# NUC123AE_v1 register map
File version: 1.0
Registers are 32-bit, read-write, reset 0x0 unless marked. A register's access mark holds for its fields unless they carry their own. Offsets are from the block's base; [hi:lo] are bit positions; {n}, {i} and the like mark numbered series; 'fields as' and 'values as' point back to an identical list.

## GCR — GCR Register Map
Base 0x50000000
0x00 PDID ro reset 0x10000 (reset mask 0xFFFF0000) — Part Device Identification Number Register
  [31:0] PDID — Part Device Identification Number. This register reflects the device part number code. S/W can read this register to identify which device is used.
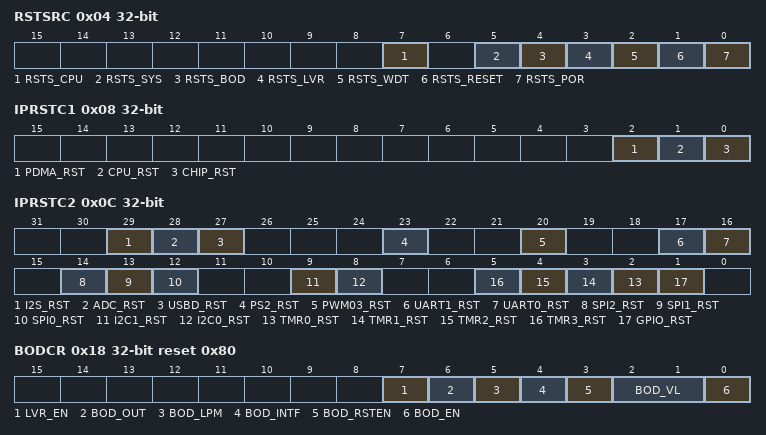
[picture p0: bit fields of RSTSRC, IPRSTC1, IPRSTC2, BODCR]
0x04 RSTSRC (reset mask 0xFFFFFF00) — System Reset Source Register
  [7] RSTS_CPU — The RSTS_CPU flag is set by hardware if software writes CPU_RST (IPRSTC1[1]) 1 to reset Cortex-M0 CPU kernel and Flash memory controller (FMC). Software can write 1 to clear this bit to zero.
    0=No reset from CPU; 1=Cortex-M0 CPU kernel and FMC are reset by software setting CPU_RST to 1
  [5] RSTS_SYS — The RSTS_SYS flag is set by the "reset signal" from the Cortex_M0 kernel to indicate the previous reset source. Software can write 1 to clear this bit to zero.
    0=No reset from Cortex_M0; 1=Cortex_M0 had issued the reset signal to reset the system by software writing 1 to bit SYSRESETREQ(AIRCR[2], Application Interrupt and Reset Control Register, address = 0xE000ED0C) in system control registers of Cortex_M0 kernel
  [4] RSTS_BOD — The RSTS_BOD flag is set by the "reset signal" from the Brown-out-Detector to indicate the previous reset source. Software can write 1 to clear this bit to zero.
    0=No reset from BOD; 1=BOD had issued the reset signal to reset the system
  [3] RSTS_LVR — The RSTS_LVR flag is set by the "reset signal" from the Low-Voltage-Reset controller to indicate the previous reset source. Software can write 1 to clear this bit to zero.
    0=No reset from LVR; 1=LVR controller had issued the reset signal to reset the system
  [2] RSTS_WDT — The RSTS_WDT flag is set by the "reset signal" from the watchdog timer to indicate the previous reset source. Software can write 1 to clear this bit to zero.
    0=No reset from watchdog timer; 1=Watchdog timer had issued the reset signal to reset the system
  [1] RSTS_RESET — The RSTS_RESET flag is set by the "reset signal" from the /RESET pin to indicate the previous reset source. Software can write 1 to clear this bit to zero.
    0=No reset from /RESET pin; 1=Pin /RESET had issued the reset signal to reset the system
  [0] RSTS_POR — The RSTS_POR flag is set by the "reset signal" from the Power-On Reset (POR) controller or bit CHIP_RST (IPRSTC1[0]) to indicate the previous reset source. Software can write 1 to clear this bit to zero.
    0=No reset from POR or CHIP_RST; 1=Power-On Reset (POR) or CHIP_RST had issued the reset signal to reset the system
0x08 IPRSTC1 — IP Reset Control Register1
  [2] PDMA_RST — PDMA Controller Reset (Write-protection). Setting this bit to 1 will generate a reset signal to the PDMA. User need to set this bit to 0 to release from reset state. This bit is the protected bit, It means programming this bit needs to write "59h", "16h", "88h" to address 0x5000_0100 to disable register protection. Refer to the register REGWRPROT at address GCR_BA+0x100.
    0=PDMA controller normal operation; 1=PDMA controller reset
  [1] CPU_RST — CPU kernel one-shot reset (Write-protection Bit). Setting this bit will only reset the CPU kernel and Flash Memory Controller(FMC), and this bit will automatically return to 0 after the 2 clock cycles. This bit is the protected bit, It means programming this bit needs to write "59h", "16h", "88h" to address 0x5000_0100 to disable register protection. Refer to the register REGWRPROT at address GCR_BA+0x100
    0=CPU normal operation; 1=CPU one-shot reset
  [0] CHIP_RST — CHIP One-shot Reset (Write-protection Bit). Setting this bit will reset the whole chip, including CPU kernel and all peripherals, and this bit will automatically return to 0 after the 2 clock cycles. The CHIP_RST is same as the POR reset, all the chip controllers is reset and the chip setting from flash are also reload. For the difference between CHIP_RST and SYSRESETREQ, please refer to section 5.2.2. This bit is the protected bit, which means programming it needs to write "59h", "16h", "88h" to address 0x5000_0100 to disable register protection. Refer to the register REGWRPROT at address GCR_BA+0x100
    0=CHIP normal operation; 1=CHIP one-shot reset
0x0C IPRSTC2 — IP Reset Control Register2
  [29] I2S_RST — I2S Controller Reset
    0=I2S controller normal operation; 1=I2S controller reset
  [28] ADC_RST — ADC Controller Reset
    0=ADC controller normal operation; 1=ADC controller reset
  [27] USBD_RST — USB Device Controller Reset
    0=USB device controller normal operation; 1=USB device controller reset
  [23] PS2_RST — PS/2 Controller Reset
    0=PS/2 controller normal operation; 1=PS/2 controller reset
  [20] PWM03_RST — PWM03 controller Reset
    0=PWM03 controller normal operation; 1=PWM03 controller reset
  [17] UART1_RST — UART1 controller Reset
    0=UART1 controller normal operation; 1=UART1 controller reset
  [16] UART0_RST — UART0 controller Reset
    0=UART0 controller normal operation; 1=UART0 controller reset
  [14] SPI2_RST — SPI2 controller Reset
    0=SPI2 controller normal operation; 1=SPI2 controller reset
  [13] SPI1_RST — SPI1 controller Reset
    0=SPI1 controller normal operation; 1=SPI1 controller reset
  [12] SPI0_RST — SPI0 controller Reset
    0=SPI0 controller normal operation; 1=SPI0 controller reset
  [9] I2C1_RST — I2C1 controller Reset
    0=I2C1 controller normal operation; 1=I2C1 controller reset
  [8] I2C0_RST — I2C0 controller Reset
    0=I2C0 controller normal operation; 1=I2C0 controller reset
  [n+2] TMR{n}_RST (n=0..3) — Timer{n} controller Reset
    0=Timer{n} controller normal operation; 1=Timer{n} controller reset
  [1] GPIO_RST — GPIO controller Reset
    0=GPIO controller normal operation; 1=GPIO controller reset
0x18 BODCR reset 0x80 (reset mask 0xFFFFFFF0) — Brown-out Detector Control Register
  [7] LVR_EN — Low Voltage Reset Enable (Write-protection Bit). The LVR function reset the chip when the input power voltage is lower than LVR circuit setting. LVR function is enabled by default. This bit is the protected bit, which means programming it needs to write "59h", "16h", "88h" to address 0x5000_0100 to disable register protection. Refer to the register REGWRPROT at address GCR_BA+0x100.
    0=Low Voltage Reset function Disabled; 1=Low Voltage Reset function Enabled- After enabling the bit, the LVR function will be active with 100uS delay for LVR output stable (Default)
  [6] BOD_OUT — Brown-out Detector Output Status
    0=Brown-out Detector output status is 0, which means the detected voltage is higher than BOD_VL setting or BOD_EN is 0; 1=Brown-out Detector output status is 1, which means the detected voltage is lower than BOD_VL setting. If the BOD_EN is 0, BOD function disabled , this bit always responds to 0
  [5] BOD_LPM — Brown-out Detector Low power Mode (Write-protection Bit). The BOD consumes about 100 uA in Normal mode, the low power mode can reduce the current to about 1/10 but slow the BOD response. This bit is the protected bit, which means programming this needs to write "59h", "16h", "88h" to address 0x5000_0100 to disable register protection. Refer to the register REGWRPROT at address GCR_BA+0x100.
    0=BOD operated in Normal mode (Default); 1=BOD low power mode Enabled
  [4] BOD_INTF — Brown-out Detector Interrupt Flag. Software can write 1 to clear this bit to zero.
    0=Brown-out Detector does not detect any voltage draft at VDD down through or up through the voltage of BOD_VL setting; 1=When Brown-out Detector detects the VDD is dropped down through the voltage of BOD_VL setting or the VDD is raised up through the voltage of BOD_VL setting, this bit is set to 1 and the Brown-out interrupt is requested if Brown-out interrupt is enabled
  [3] BOD_RSTEN — Brown-out Reset Enable (Write-protection Bit). While the BOD function is enabled (BOD_EN high) and BOD interrupt function is enabled (BOD_RSTEN low), BOD will assert an interrupt if BOD_OUT is high. BOD interrupt will keep till to the BOD_EN set to 0. BOD interrupt can be blocked by disabling the NVIC BOD interrupt or disabling BOD function (set BOD_EN low). The default value is set by flash controller user configuration register config0 bit[20]. This bit is the protected bit. It means programming this needs to write "59h", "16h", "88h" to address 0x5000_0100 to disable register protection. Refer to the register REGWRPROT at address GCR_BA+0x100.
    0=Brown-out "INTERRUPT" function Enabled; 1=Brown-out "RESET" function Enabled
  [2:1] BOD_VL — Brown-out Detector Threshold Voltage Selection (Write-protection Bits)
  [0] BOD_EN — Brown-out Detector Enable (Write-protection Bit). The default value is set by flash controller user configuration register config0 bit[23]. This bit is the protected bit, which means programming it needs to write "59h", "16h", "88h" to address 0x5000_0100 to disable register protection. Refer to the register REGWRPROT at address GCR_BA+0x100.
    0=Brown-out Detector function Disabled; 1=Brown-out Detector function Enabled
0x24 PORCR (reset mask 0xFFFFFF00) — Power-On-Reset Controller Register
  [15:0] POR_DIS_CODE — The register is used for the Power-On-Reset enable control (Write-protection Bits). When powered on, the POR circuit generates a reset signal to reset the whole chip function, but noise on the power may cause the POR active again. User can disable internal POR circuit to avoid unpredictable noise to cause chip reset by writing 0x5AA5 to this field. The POR function will become active again when this field is set to another value or chip is reset by other reset source, including: /RESET, Watchdog, LVR reset, BOD reset, ICE reset command and the software-chip reset function. This bit is the protected bit, which means programming it needs to write "59h", "16h", "88h" to address 0x5000_0100 to disable register protection. Refer to the register REGWRPROT at address GCR_BA+0x100.
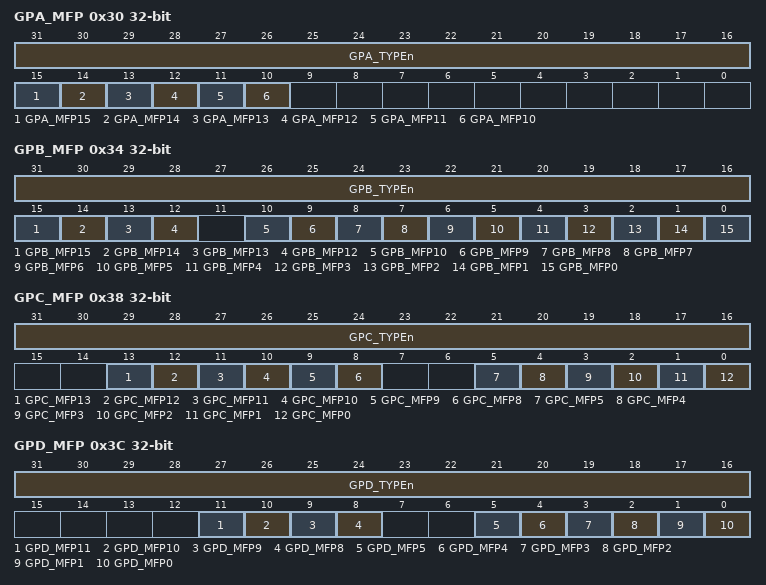
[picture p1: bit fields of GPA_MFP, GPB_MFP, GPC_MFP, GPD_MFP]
0x30 GPA_MFP — GPIOA Multiple Function and Input Type Control Register
  [31:16] GPA_TYPEn — GPA[9:0] are reserved in this chip.
    0=GPIOA[15:0] I/O input Schmitt Trigger function Disabled; 1=GPIOA[15:0] I/O input Schmitt Trigger function Enabled
  [15] GPA_MFP15 — PA.15 Pin Function Selection
  [14] GPA_MFP14 — PA.14 Pin Function Selection
  [13] GPA_MFP13 — PA.13 Pin Function Selection
  [12] GPA_MFP12 — PA.12 Pin Function Selection
  [11] GPA_MFP11 — PA.11 Pin Function Selection
  [10] GPA_MFP10 — PA.10 Pin Function Selection
0x34 GPB_MFP — GPIOB Multiple Function and Input Type Control Register
  [31:16] GPB_TYPEn
    0=GPIOB[15:0] I/O input Schmitt Trigger function Disabled; 1=GPIOB[15:0] I/O input Schmitt Trigger function Enabled
  [15] GPB_MFP15 — PB.15 Pin Function Selection
  [14] GPB_MFP14 — PB.14 Pin Function Selection
  [13] GPB_MFP13 — PB.13 Pin Function Selection
  [12] GPB_MFP12 — PB.12 Pin Function Selection
  [10] GPB_MFP10 — PB.10 Pin Function Selection
  [9] GPB_MFP9 — PB.9 Pin Function Selection
  [8] GPB_MFP8 — PB.8 Pin Function Selection
  [7] GPB_MFP7 — PB.7 Pin Function Selection
  [6] GPB_MFP6 — PB.6 Pin Function Selection
  [5] GPB_MFP5 — PB.
  [4] GPB_MFP4 — PB.4 Pin Function Selection
  [3] GPB_MFP3 — PB.3 Pin Function Selection
  [2] GPB_MFP2 — PB.2 Pin Function Selection
  [1] GPB_MFP1 — PB.1 Pin Function Selection
    0=GPIOB[1] is selected to the pin PB.1; 1=UART0 TXD0 function is selected to the pin PB.1
  [0] GPB_MFP0 — PB.0 Pin Function Selection
    0=GPIOB[0] is selected to the pin PB.0; 1=UART0 RXD0 function is selected to the pin PB.0
0x38 GPC_MFP — GPIOC Multiple Function and Input Type Control Register
  [31:16] GPC_TYPEn
    0=GPIOC[15:0] I/O input Schmitt Trigger function Disabled; 1=GPIOC[15:0] I/O input Schmitt Trigger function Enabled
  [13] GPC_MFP13 — PC.13 Pin Function Selection
  [12] GPC_MFP12 — PC.12 Pin Function Selection
  [11] GPC_MFP11 — PC.11 Pin Function Selection
    0=GPIOC[11] is selected to the pin PC.11; 1=MOSI10 (SPI1 master output, slave input pin-0) function is selected to the pin PC.11
  [10] GPC_MFP10 — PC.10 Pin Function Selection
    0=The GPIOC[10] is selected to the pin PC.10; 1=MISO10 (SPI1 master input, slave output pin-0) function is selected to the pin PC.10
  [9] GPC_MFP9 — PC.9 Pin Function Selection
    0=GPIOC[9] is selected to the pin PC.9; 1=SPICLK1 (SPI1) function is selected to the pin PC.9
  [8] GPC_MFP8 — PC.8 Pin Function Selection
  [5] GPC_MFP5 — PC.5 Pin Function Selection
  [4] GPC_MFP4 — PC.4 Pin Function Selection
  [3] GPC_MFP3 — PC.3 Pin Function Selection
  [2] GPC_MFP2 — PC.2 Pin Function Selection
  [1] GPC_MFP1 — PC.1 Pin Function Selection
  [0] GPC_MFP0 — PC.0 Pin Function Selection
0x3C GPD_MFP — GPIOD Multiple Function and Input Type Control Register
  [31:16] GPD_TYPEn
    0=GPIOD[15:0] I/O input Schmitt Trigger function Disabled; 1=GPIOD[15:0] I/O input Schmitt Trigger function Enabled
  [11] GPD_MFP11 — PD.11 Pin Function Selection
    0=GPIOD[11] is selected to the pin PD.11; 1=/INT1 function is selected to the pin PD.11
  [10] GPD_MFP10 — PD.10 Pin Function Selection
    0=GPIOD[10] is selected to the pin PD.10; 1=CLKO function is selected to the pin PD.10
  [9] GPD_MFP9 — PD.9 Pin Function Selection
  [8] GPD_MFP8 — PD.8 Pin Function Selection
    0=GPIOD[8] is selected to the pin PD8; 1=MOSI10 (SPI1 master output, slave input pin-0) function is selected to the pin PD8
  [5] GPD_MFP5 — PD.5 Pin Function Selection
  [4] GPD_MFP4 — PD.4 Pin Function Selection
  [3] GPD_MFP3 — PD.3 Pin Function Selection
  [2] GPD_MFP2 — PD.2 Pin Function Selection
  [1] GPD_MFP1 — PD.1 Pin Function Selection
  [0] GPD_MFP0 — PD.0 Pin Function Selection
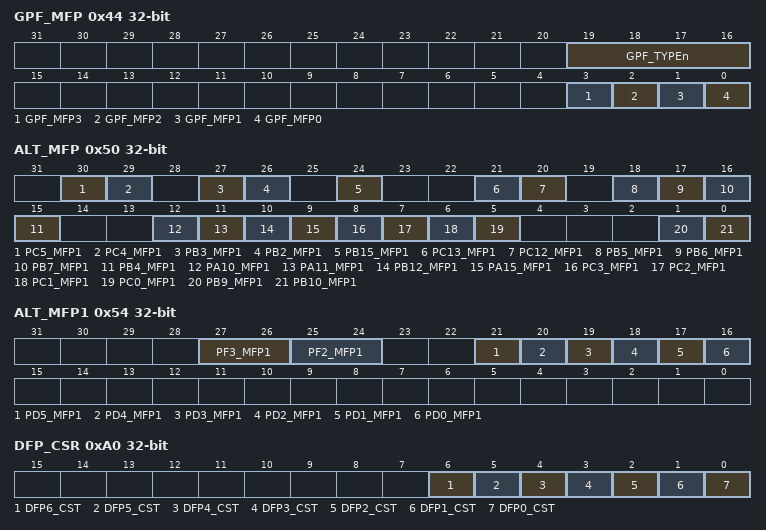
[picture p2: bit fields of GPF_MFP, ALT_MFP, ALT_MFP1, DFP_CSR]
0x44 GPF_MFP (reset mask 0xFFFFFFF0) — GPIOF Multiple Function and Input Type Control Register
  [19:16] GPF_TYPEn
    0=GPIOF[3:0] I/O input Schmitt Trigger function Disabled; 1=GPIOF[3:0] I/O input Schmitt Trigger function Enabled
  [3] GPF_MFP3 — PF.3 Pin Function Selection
  [2] GPF_MFP2 — PF.2 Pin Function Selection
  [1] GPF_MFP1 — PF.1 Pin Function Selection. The value of this bit controlled by CGPFMFP of Config0[27]. This is a read only bit.
    0=GPIOF[1] is selected to the pin PF.1; 1=XT1_IN function is selected to the pin PF.1
  [0] GPF_MFP0 — PF.0 Pin Function Selection. The value of this bit controlled by CGPFMFP of Config0[27]. This is a read only bit.
    0=GPIOF[0] is selected to the pin PF.0; 1=XT1_OUT function is selected to the pin PF.0
0x50 ALT_MFP — Alternative Multiple Function Pin Control Register
  [30] PC5_MFP1 — PC.5 Pin Function Selection
  [29] PC4_MFP1 — PC.4 Pin Function Selection
  [27] PB3_MFP1 — PB.3 Pin Alternate Function Selection
  [26] PB2_MFP1 — PB.2 Pin Alternate Function Selection
  [24] PB15_MFP1 — PB.15 Pin Alternate Function Selection
  [21] PC13_MFP1 — PC.13 Pin Function Selection
  [20] PC12_MFP1 — PC.12 Pin Function Selection
  [18] PB5_MFP1 — PB.
  [17] PB6_MFP1 — PB.6 Pin Alternate Function Selection
  [16] PB7_MFP1 — PB.7 Pin Alternate Function Selection
  [15] PB4_MFP1 — PB.4 Pin Function Selection
  [12] PA10_MFP1 — PA.10 Pin Function Selection
  [11] PA11_MFP1 — PA.11 Pin Function Selection
  [10] PB12_MFP1 — PB.12 Pin Alternate Function Selection
  [9] PA15_MFP1 — PA.15 Pin Alternate Function Selection
  [8] PC3_MFP1 — PC.3 Pin Alternate Function Selection
  [7] PC2_MFP1 — PC.2 Pin Alternate Function Selection
  [6] PC1_MFP1 — PC.1 Pin Alternate Function Selection
  [5] PC0_MFP1 — PC.0 Pin Function Selection
  [1] PB9_MFP1 — PB.9 Pin Alternate Function Selection
  [0] PB10_MFP1 — PB.10 Pin Alternate Function Selection
0x54 ALT_MFP1 — Alternative Multiple Function Pin Control Register1
  [27:26] PF3_MFP1 — PF.3 Pin Function Selection
  [25:24] PF2_MFP1 — PF.2 Pin Function Selection
  [21] PD5_MFP1 — PD.5 Pin Function Selection
  [20] PD4_MFP1 — PD.4 Pin Function Selection
  [19] PD3_MFP1 — PD.3 Pin Function Selection
  [18] PD2_MFP1 — PD.2 Pin Function Selection
  [17] PD1_MFP1 — PD.1 Pin Function Selection
  [16] PD0_MFP1 — PD.0 Pin Function Selection
0xA0 DFP_CSR ro — Pin Conflict Status
  [6] DFP6_CST — Conflict Status of PB.7
    0=PB.7 worked normally; 1=PB.7 is conflicted
  [5] DFP5_CST — Conflict Status of PB.6
    0=PB.6 worked normally; 1=PB.6 is conflicted
  [4] DFP4_CST — Conflict Status of PB.5
    0=PB.5 worked normally; 1=PB.5 is conflicted
  [3] DFP3_CST — Conflict Status of PB.4
    0=PB.4 worked normally; 1=PB.4 is conflicted
  [2] DFP2_CST — Conflict Status of PD.11
    0=PD.11 worked normally; 1=PD.11 is conflicted
  [1] DFP1_CST — Conflict Status of PD.10
    0=PD.10 worked normally; 1=PD.10 is conflicted
  [0] DFP0_CST — Conflict Status of PD.9
    0=PD.9 worked normally; 1=PD.9 is conflicted
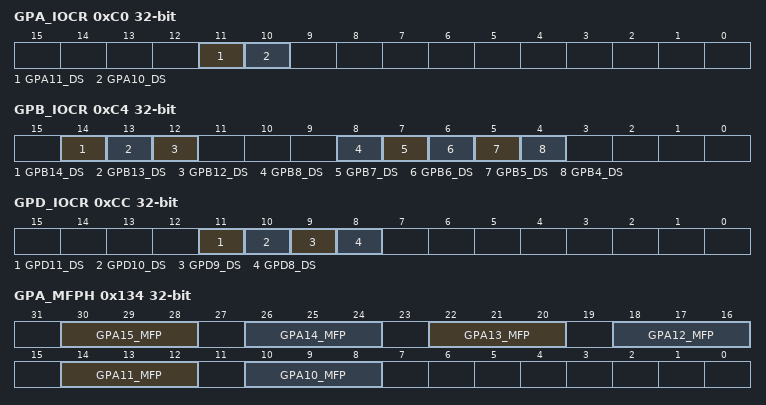
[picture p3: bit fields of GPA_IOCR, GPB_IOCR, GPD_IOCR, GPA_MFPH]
0xC0 GPA_IOCR — GPIOA IO Control Register
  [11] GPA11_DS — PA.11 Pin Driving Strength Selection
    0=PA.11 strong driving strength mode Disabled; 1=PA.11 strong driving strength mode Enabled
  [10] GPA10_DS — PA.10 Pin Driving Strength Selection
    0=PA.10 strong driving strength mode Disabled; 1=PA.10 strong driving strength mode Enabled
0xC4 GPB_IOCR — GPIOB IO Control Register
  [14] GPB14_DS — PB.14 Pin Driving Strength Selection
    0=PB.14 strong driving strength mode Disabled; 1=PB.14 strong driving strength mode Enabled
  [13] GPB13_DS — PB.13 Pin Driving Strength Selection
    0=PB.13 strong driving strength mode Disabled; 1=PB.13 strong driving strength mode Enabled
  [12] GPB12_DS — PB.12 Pin Driving Strength Selection
    0=PB.12 strong driving strength mode Disabled; 1=PB.12 strong driving strength mode Enabled
  [8] GPB8_DS — PB.8 Pin Driving Strength Selection
    0=PB.8 strong driving strength mode Disabled; 1=PB.8 strong driving strength mode Enabled
  [7] GPB7_DS — PB.7 Pin Driving Strength Selection
    0=PB.7 strong driving strength mode Disabled; 1=PB.7 strong driving strength mode Enabled
  [6] GPB6_DS — PB.6 Pin Driving Strength Selection
    0=PB.6 strong driving strength mode Disabled; 1=PB.6 strong driving strength mode Enabled
  [5] GPB5_DS — PB.5 Pin Driving Strength Selection
    0=PB.5 strong driving strength mode Disabled; 1=PB.5 strong driving strength mode Enabled
  [4] GPB4_DS — PB.4 Pin Driving Strength Selection
    0=PB.4 strong driving strength mode Disabled; 1=PB.4 strong driving strength mode Enabled
0xCC GPD_IOCR — GPIOD IO Control Register
  [11] GPD11_DS — PD.11 Pin Driving Strength Selection
    0=PD.11 strong driving strength mode Disabled; 1=PD.11 strong driving strength mode Enabled
  [10] GPD10_DS — PD.10 Pin Driving Strength Selection
    0=PD.10 strong driving strength mode Disabled; 1=PD.10 strong driving strength mode Enabled
  [9] GPD9_DS — PD.9 Pin Driving Strength Selection
    0=PD.9 strong driving strength mode Disabled; 1=PD.9 strong driving strength mode Enabled
  [8] GPD8_DS — PD.8 Pin Driving Strength Selection
    0=PD.8 strong driving strength mode Disabled; 1=PD.8 strong driving strength mode Enabled
0x100 REGWRPROT — Register Write-Protection Control Register
  [0] REGPROTDIS ro — Register Write-Protection Disable index (Read Only). The Protected registers are: IPRSTC1: address 0x5000_0008. BODCR: address 0x5000_0018. PORCR: address 0x5000_0024. PWRCON: address 0x5000_0200 (bit[6] is not protected for power wake-up interrupt clear). APBCLK bit[0]: address 0x5000_0208 (bit[0] is watchdog clock enabled). CLKSEL0: address 0x5000_0210 (for HCLK and CPU STCLK clock source select). CLKSEL1 bit[1:0]: address 0x5000_0214 (for watchdog clock source select). ISPCON: address 0x5000_C000 (Flash ISP Control register). WTCR: address 0x4000_4000. FATCON: address 0x5000_C018
    0=Write-protection Enabled for writing protected registers. Any write to the protected register is ignored; 1=Write-protection Disabled for writing protected registers
  [7:0] REGWRPROT wo — Register Write-Protection Code (Write Only). Some registers have write-protection function. Writing these registers has to disable the protected function by writing the sequence value "59h", "16h", "88h" to this field. After this sequence is completed, the REGPROTDIS bit will be set to 1 and write-protection registers can be normal write.
0x12C MFP_CSS ro — GPIO Multiple Function Control Select Status Register
  [0] NEW_MFP — New Multiple Function Control Select. This is read only bit. When software write any one of new multiple function control registers, this bit will auto set to 1 and the pin's multiple function is controlled by new multiple function control register
    0=Old multiple function control is selected; 1=New multiple function control is selected
0x134 GPA_MFPH — GPIOA Multiple Function High Byte Control Register
  [30:28] GPA15_MFP — PA.15 Pin Function Selection
  [26:24] GPA14_MFP — PA.14 Pin Function Selection
  [22:20] GPA13_MFP — PA.13 Pin Function Selection
  [18:16] GPA12_MFP — PA.12 Pin Function Selection
  [14:12] GPA11_MFP — PA.11 Pin Function Selection
  [10:8] GPA10_MFP — PA.10 Pin Function Selection
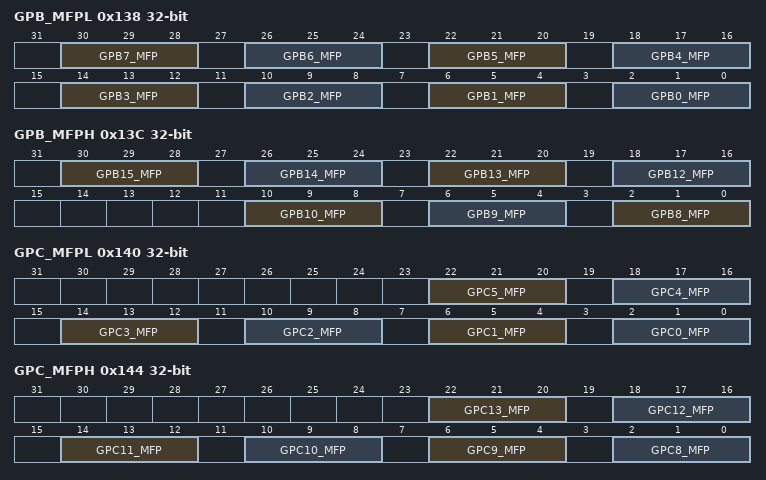
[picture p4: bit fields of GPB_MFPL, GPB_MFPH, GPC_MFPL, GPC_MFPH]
0x138 GPB_MFPL — GPIOB Multiple Function Low Byte Control Register
  [30:28] GPB7_MFP — PB.7 Pin Function Selection
  [26:24] GPB6_MFP — PB.6 Pin Function Selection
  [22:20] GPB5_MFP — PB.
  [18:16] GPB4_MFP — PB.4 Pin Function Selection
  [14:12] GPB3_MFP — PB.3 Pin Function Selection
  [10:8] GPB2_MFP — PB.2 Pin Function Selection
  [6:4] GPB1_MFP — PB.1 Pin Function Selection
  [2:0] GPB0_MFP — PB.0 Pin Function Selection
0x13C GPB_MFPH — GPIOB Multiple Function High Byte Control Register
  [30:28] GPB15_MFP — PB.15 Pin Function Selection
  [26:24] GPB14_MFP — PB.14 Pin Function Selection
  [22:20] GPB13_MFP — PB.13 Pin Function Selection
  [18:16] GPB12_MFP — PB.12 Pin Function Selection
  [10:8] GPB10_MFP — PB.10 Pin Function Selection
  [6:4] GPB9_MFP — PB.9 Pin Function Selection
  [2:0] GPB8_MFP — PB.8 Pin Function Selection
0x140 GPC_MFPL — GPIOC Multiple Function Low Byte Control Register
  [22:20] GPC5_MFP — PC.5 Pin Function Selection
  [18:16] GPC4_MFP — PC.4 Pin Function Selection
  [14:12] GPC3_MFP — PC.3 Pin Function Selection
  [10:8] GPC2_MFP — PC.2 Pin Function Selection
  [6:4] GPC1_MFP — PC.1 Pin Function Selection
  [2:0] GPC0_MFP — PC.0 Pin Function Selection
0x144 GPC_MFPH — GPIOC Multiple Function High Byte Control Register
  [22:20] GPC13_MFP — PC.13 Pin Function Selection
  [18:16] GPC12_MFP — PC.12 Pin Function Selection
  [14:12] GPC11_MFP — PC.11 Pin Function Selection
  [10:8] GPC10_MFP — PC.10 Pin Function Selection
  [6:4] GPC9_MFP — PC.9 Pin Function Selection
  [2:0] GPC8_MFP — PC.8 Pin Function Selection
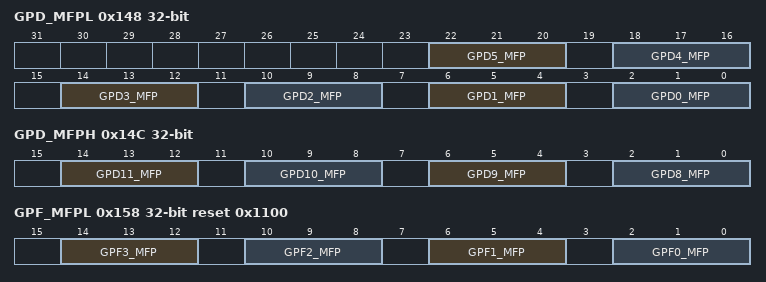
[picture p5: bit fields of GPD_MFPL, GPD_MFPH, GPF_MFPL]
0x148 GPD_MFPL — GPIOD Multiple Function Low Byte Control Register
  [22:20] GPD5_MFP — PD.5 Pin Function Selection
  [18:16] GPD4_MFP — PD.4 Pin Function Selection
  [14:12] GPD3_MFP — PD.3 Pin Function Selection
  [10:8] GPD2_MFP — PD.2 Pin Function Selection
  [6:4] GPD1_MFP — PD.1 Pin Function Selection
  [2:0] GPD0_MFP — PD.0 Pin Function Selection
0x14C GPD_MFPH — GPIOD Multiple Function High Byte Control Register
  [14:12] GPD11_MFP — PD.11 Pin Function Selection
  [10:8] GPD10_MFP — PD.10 Pin Function Selection
  [6:4] GPD9_MFP — PD.9 Pin Function Selection
  [2:0] GPD8_MFP — PD.8 Pin Function Selection
0x158 GPF_MFPL reset 0x1100 (reset mask 0xFFFFFF00) — GPIOF Multiple Function Low Byte Control Register
  [14:12] GPF3_MFP — PF.3 Pin Function Selection
  [10:8] GPF2_MFP — PF.2 Pin Function Selection
  [6:4] GPF1_MFP — PF.1 Pin Function Selection
    values as GPF_MFP.GPF_MFP1
  [2:0] GPF0_MFP — PF.0 Pin Function Selection
    values as GPF_MFP.GPF_MFP0
